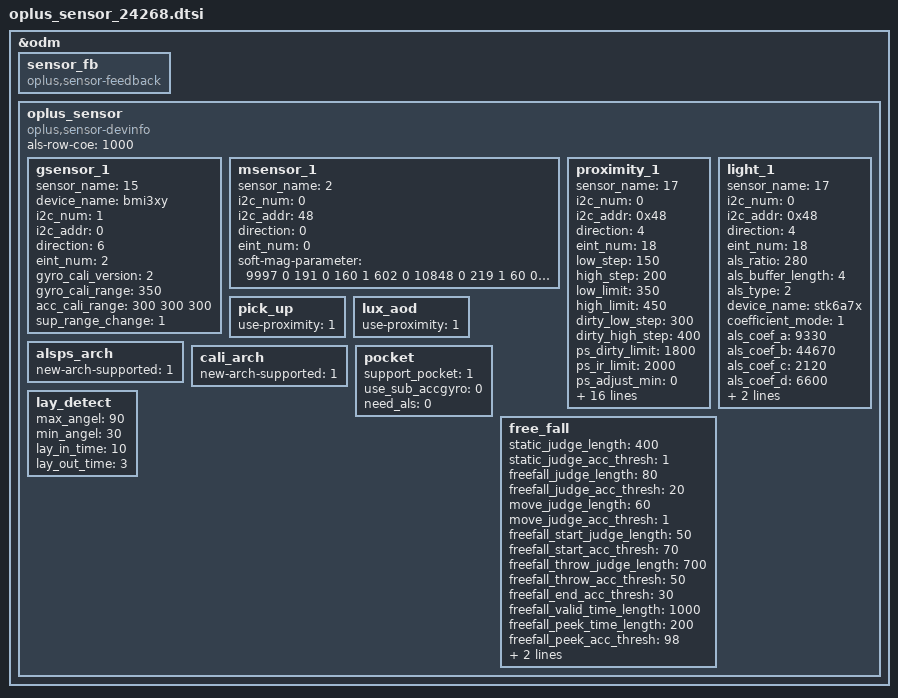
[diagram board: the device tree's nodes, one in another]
&odm {
	sensor_fb: sensor_fb {
		compatible = "oplus,sensor-feedback";
	};
	oplus_sensor:oplus_sensor {
		compatible = "oplus,sensor-devinfo";
		als-row-coe = <1000>;
		/* sensor start */
       	/*
		enum {
			LIS3DH,
			LSM6DS3,
			BMI160,
			LIS2HH12,
			LSM6DSM,
			BMI2XY,
			LSM6DSO,
			ICM4X6XX,
			ICM4263X,
			SC7A20,
			MC34X9,
		};
		*/
		gsensor_1: gsensor_1 {
			status = "okay";
			sensor_name = <15>;//BMI3XY
			device_name = "bmi3xy";
			i2c_num = <1>;
			i2c_addr = <0>;
			direction = <6>;
			eint_num = <2>;
			gyro_cali_version= <2>;
			gyro_cali_range =<350>;
			acc_cali_range= <300 300 300>;
			sup_range_change = <1>;
		};
		/*
		enum {
			AKM09911,
			MMC3530,
			MMC5603,
			MXG4300,
		};
		*/
		msensor_1: msensor_1 {
			status = "okay";
			sensor_name = <2>;//MMC5603
			i2c_num = <0>;
			i2c_addr = <48>;
			direction = <0>;
			eint_num = <0>;
			soft-mag-parameter = <9997 0 191 0 160 1 602 0 10848 0 219 1 60 0 122 1 10937 0>; //无NFC
		};
		/*
		enum {
			TMD2725,
			APSD9922,
			STK3335,
			STK3331,
			STK2232,
			TCS3701,
			STK32600,
			STK33502,
			MN78911,
		};
		*/
		proximity_1: proximity_1 {
			status = "okay";
			sensor_name = <17>; //stk63701
			i2c_num = <0>;
			i2c_addr = <0x48>;
			direction = <4>;
			eint_num = <18>;
			low_step = <150>;
			high_step = <200>;
			low_limit = <350>;
			high_limit = <450>;
			dirty_low_step = <300>;
			dirty_high_step = <400>;
			ps_dirty_limit = <1800>;
			ps_ir_limit = <2000>;
			ps_adjust_min = <0>;
			ps_adjust_max = <1850>;
			sampling_count = <5>;
			step_max = <400>;
			step_min = <100>;
			step_div = <2000>;
			anti_shake_delta = <70>;
			dynamic_cali_max = <2000>;
			raw2offset_radio = <1000>;
			offset_max = <60000>;
			offset_range_min = <0>;
			offset_range_max = <65534>;
			force_cali_limit = <2000>;
			cali_jitter_limit = <20>;
			cal_offset_margin = <3000>;
			parameter-number = <6>;
			sensor-reg = <0x05 0x20
					0x02 0x73
					0x03 0x26>;
		};
		light_1: light_1 {
			status = "okay";
			sensor_name = <17>; //stk63701
			i2c_num = <0>;
			i2c_addr = <0x48>;
			direction = <4>;
			eint_num = <18>;
			als_ratio = <280>;
			als_buffer_length =<4>;
			als_type = <2>;//<1-normal;2-under screen;3-normal needed compensation>
			device_name = "stk6a7x";
			coefficient_mode = <1>;
			als_coef_a = <9330>; //*100
			als_coef_b = <44670>; //*100
			als_coef_c = <2120>; //*100
			als_coef_d = <6600>; //*100
			als_coef_e = <9000>; //*100
			als_coef_ratio = <50>;
		};
		pick_up: pick_up {
			status = "okay";
			use-proximity = <1>;
		};
		lux_aod: lux_aod {
			status = "okay";
			use-proximity = <1>;
		};
		alsps_arch: alsps_arch {
			status = "okay";
			new-arch-supported = <1>;
		};
		cali_arch: cali_arch {
			status = "okay";
			new-arch-supported = <1>;
		};
		pocket: pocket {
			status = "okay";
			support_pocket = <1>;
			use_sub_accgyro = <0>;
			need_als = <0>;
		};
		lay_detect: lay_detect {
			status = "okay";
			max_angel = <90>;
			min_angel = <30>;
			lay_in_time = <10>;
			lay_out_time = <3>;
		};
		free_fall: free_fall {
			status = "okay";
			static_judge_length = <400>;
			static_judge_acc_thresh = <1>;
			freefall_judge_length = <80>;
			freefall_judge_acc_thresh = <20>;
			move_judge_length = <60>;
			move_judge_acc_thresh = <1>;
			freefall_start_judge_length  = <50>;
			freefall_start_acc_thresh = <70>;
			freefall_throw_judge_length = <700>;
			freefall_throw_acc_thresh = <50>;
			freefall_end_acc_thresh = <30>;
			freefall_valid_time_length = <1000>;
			freefall_peek_time_length = <200>;
			freefall_peek_acc_thresh = <98>;
			freefall_material_thresh = <900>;
			valid_peek_interval_thresh = <10000>;
		};
	};
/* sensor end */
};
